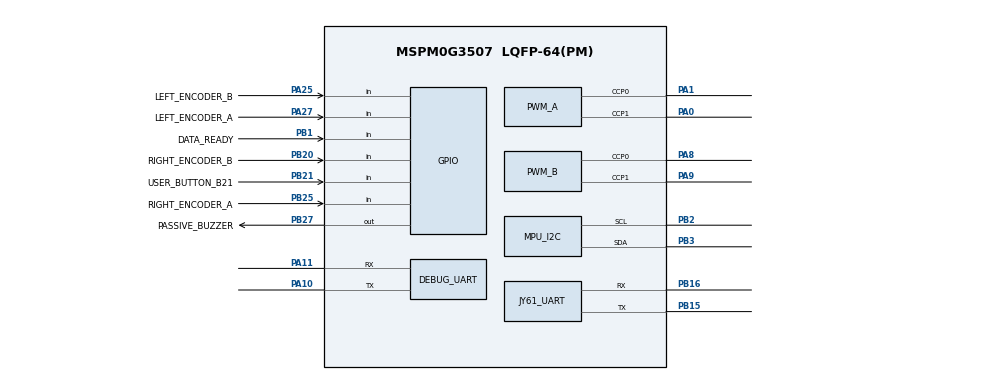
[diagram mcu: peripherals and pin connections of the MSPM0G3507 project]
/**
 * Car project, MSPM0G3507 + AT8236 + dual MG513X Hall encoder motors.
 * User wiring: PA0/PA1/PA8/PA9 = AIN1/AIN2/BIN1/BIN2.
 * Encoders: E1A/E1B/E2A/E2B = PA27/PA25/PB25/PB20.
 * JY61S UART mode: UART2 PB15=TX/PB16=RX. UART0 PA10/PA11 remains debug.
 * Passive buzzer PB27; PB1/PB2/PB3 are no longer used by the active IMU path.
 * PB21 is the board user button; motors stay at zero PWM until a deliberate press.
 * @cliArgs --device "MSPM0G350X" --package "LQFP-64(PM)" --part "Default"
 * @v2CliArgs --device "MSPM0G3507" --package "LQFP-64(PM)"
 * @versions {"tool":"1.26.2+4477"}
 */
const SYSCTL = scripting.addModule("/ti/driverlib/SYSCTL");
const GPIO = scripting.addModule("/ti/driverlib/GPIO", {}, false);
const GPIO_ENCODERS = GPIO.addInstance();
const GPIO_BUTTONS = GPIO.addInstance();
const PWM = scripting.addModule("/ti/driverlib/PWM", {}, false);
const PWM_A = PWM.addInstance();
const PWM_B = PWM.addInstance();
const TIMER = scripting.addModule("/ti/driverlib/TIMER", {}, false);
const CONTROL_TIMER = TIMER.addInstance();
const UART = scripting.addModule("/ti/driverlib/UART", {}, false);
const DEBUG_UART = UART.addInstance();
const JY61_UART = UART.addInstance();
const I2C = scripting.addModule("/ti/driverlib/I2C", {}, false);
const MPU_I2C = I2C.addInstance();
const Board = scripting.addModule("/ti/driverlib/Board", {}, false);

SYSCTL.forceDefaultClkConfig = true;

GPIO_ENCODERS.$name = "ENCODERS";
GPIO_ENCODERS.associatedPins.create(4);
GPIO_ENCODERS.associatedPins[0].$name = "LEFT_ENCODER_A";
GPIO_ENCODERS.associatedPins[0].direction = "INPUT";
GPIO_ENCODERS.associatedPins[0].interruptEn = true;
GPIO_ENCODERS.associatedPins[0].polarity = "RISE";
GPIO_ENCODERS.associatedPins[0].pin.$assign = "PA27";
GPIO_ENCODERS.associatedPins[1].$name = "LEFT_ENCODER_B";
GPIO_ENCODERS.associatedPins[1].direction = "INPUT";
GPIO_ENCODERS.associatedPins[1].pin.$assign = "PA25";
GPIO_ENCODERS.associatedPins[2].$name = "RIGHT_ENCODER_A";
GPIO_ENCODERS.associatedPins[2].direction = "INPUT";
GPIO_ENCODERS.associatedPins[2].interruptEn = true;
GPIO_ENCODERS.associatedPins[2].polarity = "RISE";
GPIO_ENCODERS.associatedPins[2].pin.$assign = "PB25";
GPIO_ENCODERS.associatedPins[3].$name = "RIGHT_ENCODER_B";
GPIO_ENCODERS.associatedPins[3].direction = "INPUT";
GPIO_ENCODERS.associatedPins[3].pin.$assign = "PB20";

const GPIO_MPU = GPIO.addInstance();
GPIO_MPU.$name = "MPU6050_INT";
GPIO_MPU.associatedPins.create(1);
GPIO_MPU.associatedPins[0].$name = "DATA_READY";
GPIO_MPU.associatedPins[0].direction = "INPUT";
GPIO_MPU.associatedPins[0].interruptEn = true;
GPIO_MPU.associatedPins[0].polarity = "RISE";
GPIO_MPU.associatedPins[0].pin.$assign = "PB1";

const GPIO_BEEPER = GPIO.addInstance();
GPIO_BEEPER.$name = "BEEPER";
GPIO_BEEPER.associatedPins.create(1);
GPIO_BEEPER.associatedPins[0].$name = "PASSIVE_BUZZER";
GPIO_BEEPER.associatedPins[0].direction = "OUTPUT";
GPIO_BEEPER.associatedPins[0].pin.$assign = "PB27";

GPIO_BUTTONS.$name = "START_BUTTON";
GPIO_BUTTONS.associatedPins[0].$name = "USER_BUTTON_B21";
GPIO_BUTTONS.associatedPins[0].direction = "INPUT";
GPIO_BUTTONS.associatedPins[0].internalResistor = "PULL_UP";
GPIO_BUTTONS.associatedPins[0].pin.$assign = "PB21";

/* User motor inputs: TIMG8_C1 -> PA0/AIN1, TIMG8_C0 -> PA1/AIN2. */
PWM_A.$name = "MOTOR_A_PWM";
PWM_A.timerCount = 3200;
PWM_A.clockPrescale = 1;
PWM_A.clockDivider = 1;
PWM_A.timerStartTimer = true;
PWM_A.pwmMode = "EDGE_ALIGN_UP";
PWM_A.peripheral.$assign = "TIMG8";
PWM_A.peripheral.ccp0Pin.$assign = "PA1";
PWM_A.peripheral.ccp1Pin.$assign = "PA0";
PWM_A.PWM_CHANNEL_0.$name = "AIN2_PWM";
PWM_A.PWM_CHANNEL_0.dutyCycle = 0;
PWM_A.PWM_CHANNEL_1.$name = "AIN1_PWM";
PWM_A.PWM_CHANNEL_1.dutyCycle = 0;

/* User motor inputs: TIMA0_C0 -> PA8/BIN1, TIMA0_C1 -> PA9/BIN2. */
PWM_B.$name = "MOTOR_B_PWM";
PWM_B.timerCount = 3200;
PWM_B.clockPrescale = 1;
PWM_B.clockDivider = 1;
PWM_B.timerStartTimer = true;
PWM_B.pwmMode = "EDGE_ALIGN_UP";
PWM_B.peripheral.$assign = "TIMA0";
PWM_B.peripheral.ccp0Pin.$assign = "PA8";
PWM_B.peripheral.ccp1Pin.$assign = "PA9";
PWM_B.PWM_CHANNEL_0.$name = "BIN1_PWM";
PWM_B.PWM_CHANNEL_0.dutyCycle = 0;
PWM_B.PWM_CHANNEL_1.$name = "BIN2_PWM";
PWM_B.PWM_CHANNEL_1.dutyCycle = 0;

CONTROL_TIMER.$name = "CONTROL_TICK";
CONTROL_TIMER.timerMode = "PERIODIC";
CONTROL_TIMER.timerPeriod = "5 ms";
CONTROL_TIMER.timerStartTimer = true;
CONTROL_TIMER.interrupts = ["ZERO"];
CONTROL_TIMER.peripheral.$assign = "TIMG12";

/* JY61S IIC mode exposes the internal MPU6050 raw bus: I2C1 PB2=SCL, PB3=SDA. */
MPU_I2C.$name = "MPU6050_I2C";
MPU_I2C.basicEnableController = true;
MPU_I2C.basicControllerStandardBusSpeed = "Fast";
MPU_I2C.peripheral.$assign = "I2C1";
MPU_I2C.peripheral.sclPin.$assign = "PB2";
MPU_I2C.peripheral.sdaPin.$assign = "PB3";
MPU_I2C.sclPinConfig.enableConfig = true;
MPU_I2C.sclPinConfig.internalResistor = "PULL_UP";
MPU_I2C.sdaPinConfig.enableConfig = true;
MPU_I2C.sdaPinConfig.internalResistor = "PULL_UP";

/* Tianmengxing on-board CH340E debug UART: UART0 on PA10/PA11. */
DEBUG_UART.$name = "DEBUG_UART";
DEBUG_UART.enableFIFO = true;
DEBUG_UART.rxFifoThreshold = "DL_UART_RX_FIFO_LEVEL_ONE_ENTRY";
DEBUG_UART.txFifoThreshold = "DL_UART_TX_FIFO_LEVEL_3_4_EMPTY";
DEBUG_UART.targetBaudRate = 115200;
DEBUG_UART.enabledInterrupts = ["RX"];
DEBUG_UART.peripheral.$assign = "UART0";
DEBUG_UART.peripheral.txPin.$assign = "PA10";
DEBUG_UART.peripheral.rxPin.$assign = "PA11";

/* JY61S UART output: PB15/UART2_TX -> sensor RX, PB16/UART2_RX <- sensor TX. */
JY61_UART.$name = "JY61_UART";
JY61_UART.enableFIFO = true;
JY61_UART.rxFifoThreshold = "DL_UART_RX_FIFO_LEVEL_ONE_ENTRY";
JY61_UART.txFifoThreshold = "DL_UART_TX_FIFO_LEVEL_3_4_EMPTY";
JY61_UART.targetBaudRate = 115200;
JY61_UART.enabledInterrupts = ["RX"];
JY61_UART.peripheral.$assign = "UART2";
JY61_UART.peripheral.txPin.$assign = "PB15";
JY61_UART.peripheral.rxPin.$assign = "PB16";
